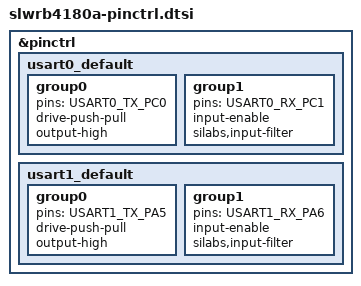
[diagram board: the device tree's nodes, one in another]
/*
 * Copyright (c) 2023 Antmicro <www.antmicro.com>
 * Copyright (c) 2024 Silicon Laboratories Inc.
 *
 * SPDX-License-Identifier: Apache-2.0
 */

#include <dt-bindings/pinctrl/silabs/xg21-pinctrl.h>

&pinctrl {
	usart0_default: usart0_default {
		group0 {
			pins = <USART0_TX_PC0>;
			drive-push-pull;
			output-high;
		};
		group1 {
			pins = <USART0_RX_PC1>;
			input-enable;
			silabs,input-filter;
		};
	};

	usart1_default: usart1_default {
		group0 {
			pins = <USART1_TX_PA5>;
			drive-push-pull;
			output-high;
		};
		group1 {
			pins = <USART1_RX_PA6>;
			input-enable;
			silabs,input-filter;
		};
	};
};
